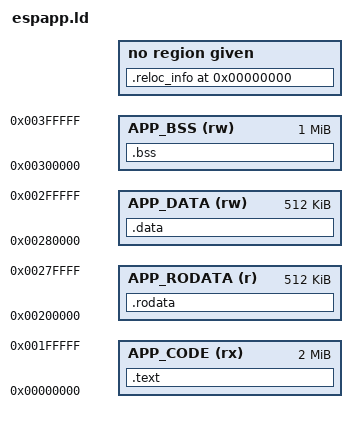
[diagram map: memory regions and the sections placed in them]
/*
 * ESP-AppOS Application Linker Script v1.0
 * Target: ESP32-S3 (Xtensa LX7) - Position Independent Code (.espapp)
 * 
 * DESIGN NOTES:
 * - All origins are VIRTUAL. The loader maps them to PSRAM at runtime.
 * - Sections MUST be 4-byte aligned (Xtensa LX7 requirement).
 * - NO absolute addresses allowed. All references must be PC-relative or via GOT.
 * - .bss is NOT stored in the .espapp file; loader zero-fills it.
 * - Custom __espapp_* symbols are used by post-build tool to extract section sizes.
 */

OUTPUT_FORMAT("elf32-xtensa-le")
OUTPUT_ARCH(xtensa)
ENTRY(app_main)

/* Virtual memory regions - origins are placeholders, not physical addresses */
MEMORY
{
    /* Code region: executable, read-only */
    APP_CODE   (rx)  : ORIGIN = 0x00000000, LENGTH = 2M
    
    /* Read-only data: constants, strings, literal pools */
    APP_RODATA (r)   : ORIGIN = 0x00200000, LENGTH = 512K
    
    /* Initialized RW data: globals with non-zero init values */
    APP_DATA   (rw)  : ORIGIN = 0x00280000, LENGTH = 512K
    
    /* Zero-init data: NOT included in binary output */
    APP_BSS    (rw)  : ORIGIN = 0x00300000, LENGTH = 1M
}

/* Minimum alignment for all sections (Xtensa LX7 32-bit bus) */
__ESPAPP_ALIGN = 4;

SECTIONS
{
    /* ============================================================
     * CODE SECTION (.text)
     * Must be first in output. Entry point must be at offset 0.
     * ============================================================ */
    .text ALIGN(__ESPAPP_ALIGN) :
    {
        /* Entry point MUST be at the very start of code section */
        KEEP(*(.entry.app_main))
        *(.entry.*)
        
        /* Main application code */
        *(.text)
        *(.text.*)
        
        /* Xtensa literal pool (L32R targets) - MUST be within 256KB of code */
        *(.literal.text)
        *(.literal.*)
        
        /* Constructors/destructors if needed (rare in embedded apps) */
        KEEP(*(.init_array))
        KEEP(*(.fini_array))
        
        . = ALIGN(__ESPAPP_ALIGN);
    } > APP_CODE
    
    /* Symbol for post-build tool: code section size */
    __espapp_code_start = ADDR(.text);
    __espapp_code_end = ALIGN(ADDR(.text) + SIZEOF(.text), __ESPAPP_ALIGN);
    __espapp_code_size = __espapp_code_end - __espapp_code_start;

    /* ============================================================
     * READ-ONLY DATA SECTION (.rodata)
     * Constants, string literals, switch tables
     * ============================================================ */
    .rodata ALIGN(__ESPAPP_ALIGN) :
    {
        *(.rodata)
        *(.rodata.*)
        
        /* Xtensa literal pool for rodata references */
        *(.literal.rodata)
        
        /* Exception/unwind info (optional, include for C++ support) */
        *(.eh_frame)
        *(.gcc_except_table.*)
        
        . = ALIGN(__ESPAPP_ALIGN);
    } > APP_RODATA
    
    __espapp_rodata_start = ADDR(.rodata);
    __espapp_rodata_end = ALIGN(ADDR(.rodata) + SIZEOF(.rodata), __ESPAPP_ALIGN);
    __espapp_rodata_size = __espapp_rodata_end - __espapp_rodata_start;

    /* ============================================================
     * INITIALIZED DATA SECTION (.data)
     * Globals/statics with non-zero initial values
     * Stored in .espapp file, copied to PSRAM at load time
     * ============================================================ */
    .data ALIGN(__ESPAPP_ALIGN) :
    {
        *(.data)
        *(.data.*)
        
        /* GOT (Global Offset Table) for PIC references */
        _GLOBAL_OFFSET_TABLE_ = .;
        *(.got)
        *(.got.plt)
        
        . = ALIGN(__ESPAPP_ALIGN);
    } > APP_DATA
    
    __espapp_data_start = ADDR(.data);
    __espapp_data_end = ALIGN(ADDR(.data) + SIZEOF(.data), __ESPAPP_ALIGN);
    __espapp_data_size = __espapp_data_end - __espapp_data_start;

    /* ============================================================
     * BSS SECTION (.bss)
     * Zero-initialized data. NOT stored in .espapp binary.
     * Loader must memset this region to 0 after loading.
     * ============================================================ */
    .bss ALIGN(__ESPAPP_ALIGN) (NOLOAD) :
    {
        __espapp_bss_start = .;
        *(.bss)
        *(.bss.*)
        *(COMMON)
        . = ALIGN(__ESPAPP_ALIGN);
        __espapp_bss_end = .;
    } > APP_BSS
    
    __espapp_bss_size = __espapp_bss_end - __espapp_bss_start;

    /* ============================================================
     * RELOCATION TABLE (Custom section for post-build extraction)
     * Contains raw relocation entries generated by compiler.
     * Post-build tool parses this, converts to espapp_reloc_t format,
     * then DISCARDS this section from final binary.
     * ============================================================ */
    .reloc_info 0 (INFO) :
    {
        *(.rela.text)
        *(.rela.text.*)
        *(.rela.rodata)
        *(.rela.rodata.*)
        *(.rela.data)
        *(.rela.data.*)
        *(.rela.got)
    }

    /* ============================================================
     * DISCARDED SECTIONS
     * These must NEVER appear in the final .espapp binary
     * ============================================================ */
    /DISCARD/ :
    {
        /* Debug info - stripped for production */
        *(.debug*)
        *(.comment)
        *(.note*)
        
        /* Xtensa windowed register ABI vectors - handled by kernel */
        *(.WindowVectors.text)
        *(.Level2InterruptVector.text)
        *(.Level3InterruptVector.text)
        *(.DebugExceptionVector.text)
        *(.NMIExceptionVector.text)
        *(.KernelExceptionVector.text)
        *(.UserExceptionVector.text)
        *(.DoubleExceptionVector.text)
        
        /* Standard ELF headers not needed in flat binary */
        *(.interp)
        *(.dynsym)
        *(.dynstr)
        *(.dynamic)
        *(.hash)
        *(.gnu.hash)
    }
}

/* ============================================================
 * ASSERTIONS - Fail build if constraints violated
 * ============================================================ */

/* Entry point must exist */
ASSERT(DEFINED(app_main), "ERROR: app_main entry point not defined. App must export app_main().")

/* Code must fit in allocated region */
ASSERT(__espapp_code_size <= LENGTH(APP_CODE), 
       "ERROR: Code section exceeds 2MB limit. Optimize or split app.")

/* L32R literal pool must be reachable (256KB window from any CALL/L32R) */
ASSERT((__espapp_rodata_start - __espapp_code_start) < 256K,
       "ERROR: .rodata too far from .text. L32R instructions cannot reach literals. Move constants closer.")

/* Total loaded size sanity check */
ASSERT((__espapp_code_size + __espapp_rodata_size + __espapp_data_size) < 3M,
       "WARNING: App binary > 3MB. Load time may exceed 300ms on SDMMC.")
